# psoc6_01 register map
Vendor: Cypress Semiconductor; Series: psoc6_01; File version: 1.0
CPU: CM4 r0p1, little endian, MPU, FPU, VTOR, 3 interrupt priority bits
Registers are 32-bit, read-write, reset 0x0 unless marked. A register's access mark holds for its fields unless they carry their own. Offsets are from the block's base; [hi:lo] are bit positions; lines under a group give offsets from that group; {n}, {i} and the like mark numbered series.

## FAULT — Fault structures
Base 0x40220000
{0x0+0x100*i} STRUCT[{i}] (i=0..1) group — Fault structure
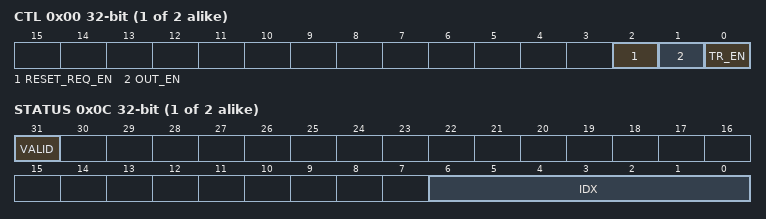
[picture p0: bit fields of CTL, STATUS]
  0x00 CTL — Fault control
    [2] RESET_REQ_EN — Reset request enable: '0': Disabled. '1': Enabled. The output reset request signal 'fault_reset_req' reflects STATUS.VALID. This reset causes a warm/soft/core reset. This warm/soft/core reset does not affect the fault logic STATUS, DATA0, ..., DATA3 registers (allowing for post soft reset failure analysis). The 'fault_reset_req' signals of the individual fault report structures are combined (logically OR'd) into a single SRSS 'fault_reset_req' signal.
    [1] OUT_EN — IO output signal enable: '0': Disabled. The IO output signal 'fault_out' is '0'. The IO output enable signal 'fault_out_en' is '0'. '1': Enabled. The IO output signal 'fault_out' reflects STATUS.VALID. The IO output enable signal 'fault_out_en' is '1'.
    [0] TR_EN — Trigger output enable: '0': Disabled. The trigger output 'tr_fault' is '0'. '1': Enabled. The trigger output 'tr_fault' reflects STATUS.VALID. The trigger can be used to initiate a Datawire transfer of the FAULT data (FAULT_DATA0 through FAULT_DATA3).
  0x0C STATUS (reset mask 0x80000000) — Fault status
    [31] VALID — Valid indication: '0': Invalid. '1': Valid. HW sets this field to '1' when new fault source data is captured. New fault source data is ONLY captured when VALID is '0'. SW can clear this field to '0' when the fault is handled (by SW).
    [6:0] IDX ro — The fault source index for which fault information is captured in DATA0 through DATA3. The fault information is fault source specific and described below. Note: this register field (and associated fault source data in DATA0 through DATA3) should only be considered valid, when VALID is '1'.
      0=MPU_0 (Bus master 0 MPU/SMPU. DATA0[31:0]: Violating address. DATA1[0]: User read. DATA1[1]: User write. DATA1[2]: User execute. DATA1[3]: Privileged read. DATA1[4]: Privileged write. DATA1[5]: Privileged execute. DATA1[6]: Non-secure. DATA1[11:8]: Master identifier. DATA1[15:12]: Protection context identifier. DATA1[31]: '0' MPU violation; '1': SMPU violation.); {v}=MPU_{v} (Bus master {v} MPU. See MPU_0 description.) (v=1..15); 16=CM4_SYS_MPU (CM4 system bus AHB-Lite interface MPU. See MPU_0 description.); 28=MS_PPU_0 (Peripheral master interface 0 PPU. DATA0[31:0]: Violating address. DATA1[0]: User read. DATA1[1]: User write. DATA1[2]: User execute. DATA1[3]: Privileged read. DATA1[4]: Privileged write. DATA1[5]: Privileged execute. DATA1[6]: Non-secure. DATA1[11:8]: Master identifier. DATA1[15:12]: Protection context identifier. DATA1[31]: '0': PPU violation, '1': peripheral bus error.); 29=MS_PPU_1 (Peripheral master interface 0 PPU. See MS_PPU_0 description.); 30=MS_PPU_2 (Peripheral master interface 1 PPU. See MS_PPU_0 description.); 31=MS_PPU_3 (Peripheral master interface 2 PPU. See MS_PPU_0 description.); 32=GROUP_PPU_0 (Peripheral group 0 PPU. DATA0[31:0]: Violating address. DATA1[0]: User read. DATA1[1]: User write. DATA1[2]: User execute. DATA1[3]: Privileged read. DATA1[4]: Privileged write. DATA1[5]: Privileged execute. DATA1[6]: Non-secure. DATA1[11:8]: Master identifier. DATA1[15:12]: Protection context identifier. DATA1[31:30]: '0': PPU violation, '1': timeout detected, '2': peripheral bus error.); {v}=GROUP_PPU_{v-32} (Peripheral group {v-32} PPU. See GROUP_PPU_0 description.) (v=33..47); 50=FLASHC_MAIN_BUS_ERROR (Flash controller, main interface, bus error: FAULT_DATA0[31:0]: Violating address. FAULT_DATA1[31]: '0': FLASH macro interface bus error; '1': memory hole. FAULT_DATA1[15:12]: Protection context identifier. FAULT_DATA1[11:8]: Master identifier.)
  {0x10+4j} DATA[{j}] (j=0..3) ro reset not defined — Fault data
    [31:0] DATA — Captured fault source data. Note: the fault source index STATUS.IDX specifies the format of the DATA registers.
  0x40 PENDING0 ro reset not defined — Fault pending 0
    [31:0] SOURCE — This field specifies the following sources: Bit 0: CM0 MPU. Bit 1: CRYPTO MPU. Bit 2: DW 0 MPU. Bit 3: DW 1 MPU. ... Bit 14: CM4 code bus MPU. Bit 15: DAP MPU. Bit 16: CM4 s+G92ystem bus MPU. Bit 28: Peripheral master interface 0 PPU. Bit 29: Peripheral master interface 1 PPU. Bit 30: Peripheral master interface 2 PPU. Bit 31: Peripheral master interface 3 PPU.
  0x44 PENDING1 ro reset not defined — Fault pending 1
    [31:0] SOURCE — This field specifies the following sources: Bit 0: Peripheral group 0 PPU. Bit 1: Peripheral group 1 PPU. Bit 2: Peripheral group 2 PPU. Bit 3: Peripheral group 3 PPU. Bit 4: Peripheral group 4 PPU. Bit 5: Peripheral group 5 PPU. Bit 6: Peripheral group 6 PPU. Bit 7: Peripheral group 7 PPU. ... Bit 15: Peripheral group 15 PPU. Bit 18: Flash controller, main interface, bus error.
  0x48 PENDING2 ro reset not defined — Fault pending 2
    [31:0] SOURCE — This field specifies the following sources: Bit 0 - 31: TBD.
  0x50 MASK0 — Fault mask 0
    [31:0] SOURCE — Fault source enables: Bits 31-0: Fault sources 31 to 0.
  0x54 MASK1 — Fault mask 1
    [31:0] SOURCE — Fault source enables: Bits 31-0: Fault sources 63 to 32.
  0x58 MASK2 — Fault mask 2
    [31:0] SOURCE — Fault source enables: Bits 31-0: Fault sources 95 to 64.
  0xC0 INTR — Interrupt
    [0] FAULT — This interrupt cause field is activated (HW sets the field to '1') when an enabled (MASK0/MASK1/MASK2) pending fault source is captured: - STATUS.VALID is set to '1'. - STATUS.IDX specifies the fault source index. - DATA0 through DATA3 captures the fault source data. SW writes a '1' to these field to clear the interrupt cause to '0'.
  0xC4 INTR_SET — Interrupt set
    [0] FAULT — SW writes a '1' to this field to set the corresponding field in the INTR register.
  0xC8 INTR_MASK — Interrupt mask
    [0] FAULT — Mask bit for corresponding field in the INTR register.
  0xCC INTR_MASKED ro — Interrupt masked
    [0] FAULT — Logical and of corresponding INTR and INTR_MASK fields.

## Notices in the file
Copyright 2016-2018, Cypress Semiconductor Corporation.  All rights reserved.
You may use this file only in accordance with the license, terms, conditions,
disclaimers, and limitations in the end user license agreement accompanying
the software package with which this file was provided.
